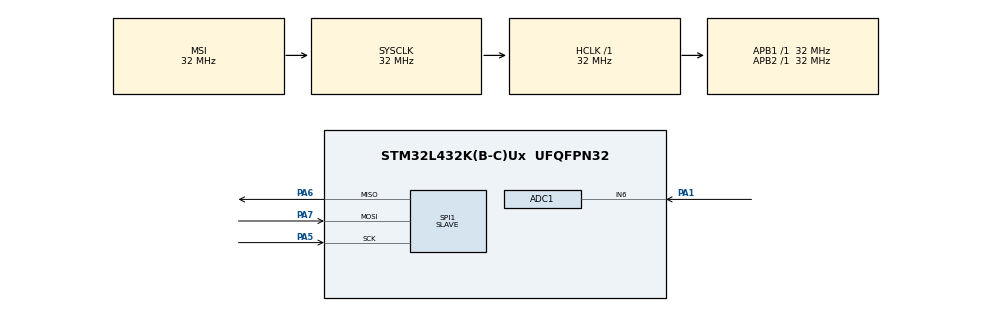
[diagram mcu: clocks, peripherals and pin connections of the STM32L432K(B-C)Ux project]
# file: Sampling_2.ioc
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ADC1.Channel-1\#ChannelRegularConversion=ADC_CHANNEL_6
ADC1.ExternalTrigConv=ADC_EXTERNALTRIG_T1_TRGO
ADC1.NbrOfConversionFlag=1
ADC1.OffsetNumber-1\#ChannelRegularConversion=ADC_OFFSET_NONE
ADC1.Rank-1\#ChannelRegularConversion=1
ADC1.Resolution=ADC_RESOLUTION_8B
ADC1.SamplingTime-1\#ChannelRegularConversion=ADC_SAMPLETIME_2CYCLES_5
ADC1.master=1
Mcu.Family=STM32L4
Mcu.Name=STM32L432K(B-C)Ux
Mcu.Package=UFQFPN32
NVIC.ADC1_IRQn=true\:0\:0\:false\:false\:true\:true\:true\:true
NVIC.PriorityGroup=NVIC_PRIORITYGROUP_4
NVIC.TIM1_BRK_TIM15_IRQn=true\:0\:0\:false\:false\:true\:true\:true\:true
NVIC.TIM1_CC_IRQn=true\:0\:0\:false\:false\:true\:true\:true\:true
NVIC.TIM1_TRG_COM_IRQn=true\:0\:0\:false\:false\:true\:true\:true\:true
NVIC.TIM1_UP_TIM16_IRQn=true\:0\:0\:false\:false\:true\:true\:true\:true
PA1.Signal=ADCx_IN6
PA5.Mode=Full_Duplex_Slave
PA5.Signal=SPI1_SCK
PA6.Mode=Full_Duplex_Slave
PA6.Signal=SPI1_MISO
PA7.Mode=Full_Duplex_Slave
PA7.Signal=SPI1_MOSI
ProjectManager.HeapSize=0x200
ProjectManager.StackSize=0x400
ProjectManager.TargetToolchain=CMake
RCC.ADCFreq_Value=64000000
RCC.AHBFreq_Value=32000000
RCC.APB1Freq_Value=32000000
RCC.APB1TimFreq_Value=32000000
RCC.APB2Freq_Value=32000000
RCC.APB2TimFreq_Value=32000000
RCC.CortexFreq_Value=32000000
RCC.HCLKFreq_Value=32000000
RCC.HSE_VALUE=8000000
RCC.HSI48_VALUE=48000000
RCC.HSI_VALUE=16000000
RCC.LSE_VALUE=32768
RCC.MSIClockRange=RCC_MSIRANGE_10
RCC.MSI_VALUE=32000000
RCC.PLLM=2
RCC.SYSCLKFreq_VALUE=32000000
RCC.USBFreq_Value=64000000
RCC.VCOOutputFreq_Value=128000000
SH.ADCx_IN6.0=ADC1_IN6,IN6-Single-Ended
SPI1.DataSize=SPI_DATASIZE_8BIT
SPI1.Direction=SPI_DIRECTION_2LINES
SPI1.Mode=SPI_MODE_SLAVE
SPI1.VirtualType=VM_SLAVE
TIM1.Period=102
TIM1.Prescaler=31
TIM1.TIM_MasterOutputTrigger=TIM_TRGO_UPDATE
VP_TIM1_VS_ClockSourceINT.Mode=Internal
board=custom

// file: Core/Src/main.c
/* USER CODE BEGIN Header */
/**
  ******************************************************************************
  * @file           : main.c
  * @brief          : Main program body
  ******************************************************************************
  * @attention
  *
  * Copyright (c) 2026 STMicroelectronics.
  * All rights reserved.
  *
  * This software is licensed under terms that can be found in the LICENSE file
  * in the root directory of this software component.
  * If no LICENSE file comes with this software, it is provided AS-IS.
  *
  ******************************************************************************
  */
/* USER CODE END Header */
#include "main.h"

ADC_HandleTypeDef hadc1;

SPI_HandleTypeDef hspi1;

TIM_HandleTypeDef htim1;

/* USER CODE BEGIN PV */
volatile uint8_t latest_sample = 0;
volatile uint8_t sample_ready = 0;

/* USER CODE END PV */

void SystemClock_Config(void);
static void MX_GPIO_Init(void);
static void MX_ADC1_Init(void);
static void MX_SPI1_Init(void);
static void MX_TIM1_Init(void);

/* USER CODE BEGIN 0 */
void HAL_ADC_ConvCpltCallback(ADC_HandleTypeDef *hadc) {
    if (hadc->Instance == ADC1) {
        latest_sample = (uint8_t)HAL_ADC_GetValue(&hadc1);
        sample_ready = 1;
    }
}
/* USER CODE END 0 */

int main(void)
{

  /* MCU Configuration--------------------------------------------------------*/

  /* Reset of all peripherals, Initializes the Flash interface and the Systick. */
  HAL_Init();

  /* Configure the system clock */
  SystemClock_Config();

  /* Initialize all configured peripherals */
  MX_GPIO_Init();
  MX_ADC1_Init();
  MX_SPI1_Init();
  MX_TIM1_Init();
  /* USER CODE BEGIN 2 */
  HAL_TIM_Base_Start(&htim1);
  HAL_ADC_Start_IT(&hadc1);
  /* USER CODE END 2 */

  /* Infinite loop */
  /* USER CODE BEGIN WHILE */
  while (1)
  {
    if (sample_ready) {
            sample_ready = 0;
            HAL_SPI_Transmit(&hspi1, &latest_sample, 1, 1);
        }
    /* USER CODE END WHILE */

  }
}

void SystemClock_Config(void)
{
  RCC_OscInitTypeDef RCC_OscInitStruct = {0};
  RCC_ClkInitTypeDef RCC_ClkInitStruct = {0};

  /** Configure the main internal regulator output voltage
  */
  if (HAL_PWREx_ControlVoltageScaling(PWR_REGULATOR_VOLTAGE_SCALE1) != HAL_OK)
  {
    Error_Handler();
  }

  /** Initializes the RCC Oscillators according to the specified parameters
  * in the RCC_OscInitTypeDef structure.
  */
  RCC_OscInitStruct.OscillatorType = RCC_OSCILLATORTYPE_MSI;
  RCC_OscInitStruct.MSIState = RCC_MSI_ON;
  RCC_OscInitStruct.MSICalibrationValue = 0;
  RCC_OscInitStruct.MSIClockRange = RCC_MSIRANGE_10;
  RCC_OscInitStruct.PLL.PLLState = RCC_PLL_NONE;
  if (HAL_RCC_OscConfig(&RCC_OscInitStruct) != HAL_OK)
  {
    Error_Handler();
  }

  /** Initializes the CPU, AHB and APB buses clocks
  */
  RCC_ClkInitStruct.ClockType = RCC_CLOCKTYPE_HCLK|RCC_CLOCKTYPE_SYSCLK
                              |RCC_CLOCKTYPE_PCLK1|RCC_CLOCKTYPE_PCLK2;
  RCC_ClkInitStruct.SYSCLKSource = RCC_SYSCLKSOURCE_MSI;
  RCC_ClkInitStruct.AHBCLKDivider = RCC_SYSCLK_DIV1;
  RCC_ClkInitStruct.APB1CLKDivider = RCC_HCLK_DIV1;
  RCC_ClkInitStruct.APB2CLKDivider = RCC_HCLK_DIV1;

  if (HAL_RCC_ClockConfig(&RCC_ClkInitStruct, FLASH_LATENCY_1) != HAL_OK)
  {
    Error_Handler();
  }
}

static void MX_ADC1_Init(void)
{

  ADC_ChannelConfTypeDef sConfig = {0};

  /** Common config
  */
  hadc1.Instance = ADC1;
  hadc1.Init.ClockPrescaler = ADC_CLOCK_ASYNC_DIV1;
  hadc1.Init.Resolution = ADC_RESOLUTION_8B;
  hadc1.Init.DataAlign = ADC_DATAALIGN_RIGHT;
  hadc1.Init.ScanConvMode = ADC_SCAN_DISABLE;
  hadc1.Init.EOCSelection = ADC_EOC_SINGLE_CONV;
  hadc1.Init.LowPowerAutoWait = DISABLE;
  hadc1.Init.ContinuousConvMode = DISABLE;
  hadc1.Init.NbrOfConversion = 1;
  hadc1.Init.DiscontinuousConvMode = DISABLE;
  hadc1.Init.ExternalTrigConv = ADC_EXTERNALTRIG_T1_TRGO;
  hadc1.Init.ExternalTrigConvEdge = ADC_EXTERNALTRIGCONVEDGE_RISING;
  hadc1.Init.DMAContinuousRequests = DISABLE;
  hadc1.Init.Overrun = ADC_OVR_DATA_PRESERVED;
  hadc1.Init.OversamplingMode = DISABLE;
  if (HAL_ADC_Init(&hadc1) != HAL_OK)
  {
    Error_Handler();
  }

  /** Configure Regular Channel
  */
  sConfig.Channel = ADC_CHANNEL_6;
  sConfig.Rank = ADC_REGULAR_RANK_1;
  sConfig.SamplingTime = ADC_SAMPLETIME_2CYCLES_5;
  sConfig.SingleDiff = ADC_SINGLE_ENDED;
  sConfig.OffsetNumber = ADC_OFFSET_NONE;
  sConfig.Offset = 0;
  if (HAL_ADC_ConfigChannel(&hadc1, &sConfig) != HAL_OK)
  {
    Error_Handler();
  }

}

static void MX_SPI1_Init(void)
{

  /* SPI1 parameter configuration*/
  hspi1.Instance = SPI1;
  hspi1.Init.Mode = SPI_MODE_SLAVE;
  hspi1.Init.Direction = SPI_DIRECTION_2LINES;
  hspi1.Init.DataSize = SPI_DATASIZE_8BIT;
  hspi1.Init.CLKPolarity = SPI_POLARITY_LOW;
  hspi1.Init.CLKPhase = SPI_PHASE_1EDGE;
  hspi1.Init.NSS = SPI_NSS_SOFT;
  hspi1.Init.FirstBit = SPI_FIRSTBIT_MSB;
  hspi1.Init.TIMode = SPI_TIMODE_DISABLE;
  hspi1.Init.CRCCalculation = SPI_CRCCALCULATION_DISABLE;
  hspi1.Init.CRCPolynomial = 7;
  hspi1.Init.CRCLength = SPI_CRC_LENGTH_DATASIZE;
  hspi1.Init.NSSPMode = SPI_NSS_PULSE_DISABLE;
  if (HAL_SPI_Init(&hspi1) != HAL_OK)
  {
    Error_Handler();
  }

}

static void MX_TIM1_Init(void)
{

  TIM_ClockConfigTypeDef sClockSourceConfig = {0};
  TIM_MasterConfigTypeDef sMasterConfig = {0};

  htim1.Instance = TIM1;
  htim1.Init.Prescaler = 31;
  htim1.Init.CounterMode = TIM_COUNTERMODE_UP;
  htim1.Init.Period = 102;
  htim1.Init.ClockDivision = TIM_CLOCKDIVISION_DIV1;
  htim1.Init.RepetitionCounter = 0;
  htim1.Init.AutoReloadPreload = TIM_AUTORELOAD_PRELOAD_DISABLE;
  if (HAL_TIM_Base_Init(&htim1) != HAL_OK)
  {
    Error_Handler();
  }
  sClockSourceConfig.ClockSource = TIM_CLOCKSOURCE_INTERNAL;
  if (HAL_TIM_ConfigClockSource(&htim1, &sClockSourceConfig) != HAL_OK)
  {
    Error_Handler();
  }
  sMasterConfig.MasterOutputTrigger = TIM_TRGO_UPDATE;
  sMasterConfig.MasterOutputTrigger2 = TIM_TRGO2_RESET;
  sMasterConfig.MasterSlaveMode = TIM_MASTERSLAVEMODE_DISABLE;
  if (HAL_TIMEx_MasterConfigSynchronization(&htim1, &sMasterConfig) != HAL_OK)
  {
    Error_Handler();
  }

}

static void MX_GPIO_Init(void)
{

  /* GPIO Ports Clock Enable */
  __HAL_RCC_GPIOA_CLK_ENABLE();

}

void Error_Handler(void)
{
  __disable_irq();
  while (1)
  {
  }
}
